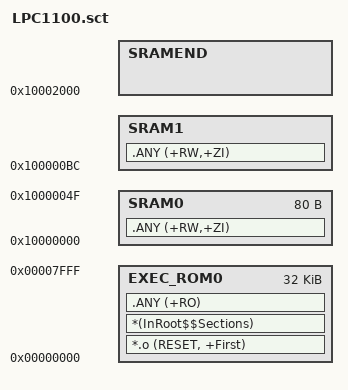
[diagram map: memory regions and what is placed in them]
; *************************************************************
; *** Scatter-Loading Description File generated by TKStudio***
; *************************************************************

LOAD_ROM0 0x00000000   ;Load region
{
    EXEC_ROM0 0x00000000 0x00008000  ; load address = execution address
    {
       *.o (RESET, +First)
       *(InRoot$$Sections)
       .ANY (+RO)
    }
    
    SRAM0 0x10000000  0x50
    {
        .ANY (+RW,+ZI)
    }

    SRAM1 0x100000BC
    {
        .ANY (+RW,+ZI)
    }

    SRAMEND 0x10002000  empty 0
    {
    
    }
}
